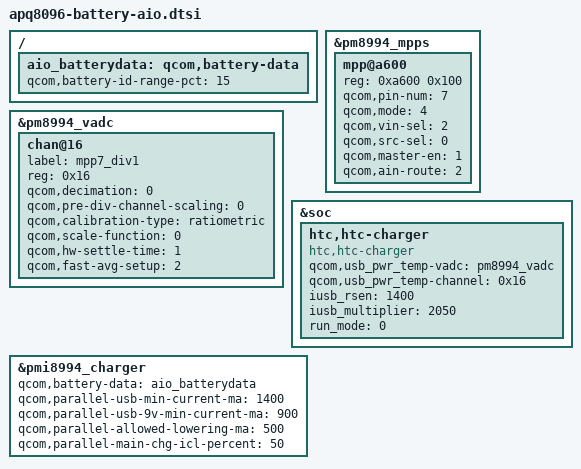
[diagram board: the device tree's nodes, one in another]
&pm8994_mpps {
	mpp@a600 { /*MPP 7*/
		reg = <0xa600 0x100>;
		qcom,pin-num = <7>;
		qcom,mode = <4>;                /* QPNP_PIN_MODE_AIN */
		qcom,vin-sel = <2>;             /* S4 1.8V */
		qcom,src-sel = <0>;             /* Constant */
		qcom,master-en = <1>;           /* Enable MPP */
		qcom,ain-route = <2>;  /* QPNP_PIN_AIN_AMUX_CH7 */
		status = "okay";
	};
};

&pm8994_vadc {
	chan@16 {
		label = "mpp7_div1";
		reg = <0x16>;
		qcom,decimation = <0>;
		qcom,pre-div-channel-scaling = <0>;
		qcom,calibration-type = "ratiometric";
		qcom,scale-function = <0>;
		qcom,hw-settle-time = <1>;
		qcom,fast-avg-setup = <2>;
	};
};

&soc {
	htc,htc-charger {
		compatible = "htc,htc-charger";
		qcom,usb_pwr_temp-vadc = <&pm8994_vadc>;
		qcom,usb_pwr_temp-channel = <0x16>; //MPP7
		iusb_rsen = <1400>;
		iusb_multiplier = <2050>;

		run_mode = <0>;
	};
};

&pmi8994_charger {
    qcom,battery-data = <&aio_batterydata>;
    qcom,parallel-usb-min-current-ma = <1400>;
    qcom,parallel-usb-9v-min-current-ma = <900>;
    qcom,parallel-allowed-lowering-ma = <500>;
    qcom,parallel-main-chg-icl-percent = <50>;
};

/ {
    aio_batterydata: qcom,battery-data {
        qcom,battery-id-range-pct = <15>;
        /delete-node/ qcom,itech-3000mah;
        #include "batterydata-aio-id1.dtsi"
        #include "batterydata-aio-id2.dtsi"
        #include "batterydata-aio-id3.dtsi"
    };
};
